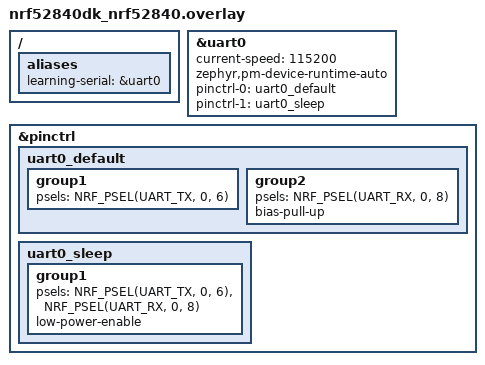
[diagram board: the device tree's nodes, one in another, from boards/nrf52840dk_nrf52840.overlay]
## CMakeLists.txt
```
cmake_minimum_required(VERSION 3.20.0)
find_package(Zephyr REQUIRED HINTS $ENV{ZEPHYR_BASE})

project(learning_zephyr_serial)

target_sources(app PRIVATE 
    src/main.c
    )

add_subdirectory(./src/app_uart)
add_subdirectory_ifdef(CONFIG_APP_USB ./src/app_usb)
```

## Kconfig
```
source "Kconfig.zephyr"

menu "Zephyr Application UART Configuration"
rsource "src/app_uart/Kconfig.app_uart"
endmenu

menu "Application Configuration"
module = APP
module-str = app
source "subsys/logging/Kconfig.template.log_config"
endmenu

menu "Application USB Device Configuration"
rsource "src/app_usb/Kconfig.app_usb"
endmenu
```

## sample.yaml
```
sample:
  description: Learning Zephyr Async Serial Sample
  name: Learning Zephyr Async Serial Sample
tests:
  sample.peripheral.learning_zephyr_serial:
    sysbuild: true
    build_only: true
    integration_platforms:
      - nrf52dk/nrf52832
      - nrf52833dk/nrf52833
      - nrf52840dk/nrf52840
      - nrf5340dk/nrf5340/cpuapp
      - nrf5340dk/nrf5340/cpuapp/ns
      - nrf54l15dk/nrf54l15/cpuapp
      - nrf54lm20dk/nrf54lm20a/cpuapp
      - nrf9151dk/nrf9151/ns
      - nrf9160dk/nrf9160/ns
    platform_allow:
      - nrf52dk/nrf52832
      - nrf52833dk/nrf52833
      - nrf52840dk/nrf52840
      - nrf5340dk/nrf5340/cpuapp
      - nrf5340dk/nrf5340/cpuapp/ns
      - nrf54l15dk/nrf54l15/cpuapp
      - nrf54lm20dk/nrf54lm20a/cpuapp
      - nrf9151dk/nrf9151/ns
      - nrf9160dk/nrf9160/ns
    tags:
      - sysbuild
```

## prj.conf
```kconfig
# use RTT as console
CONFIG_USE_SEGGER_RTT=y
CONFIG_RTT_CONSOLE=y
CONFIG_UART_CONSOLE=n

# enable logging
CONFIG_LOG=y
CONFIG_LOG_BACKEND_RTT=y
CONFIG_LOG_MODE_DEFERRED=y

CONFIG_SEGGER_RTT_MODE_NO_BLOCK_SKIP=y

# use ASYNC uart API
CONFIG_SERIAL=y
CONFIG_UART_ASYNC_API=y

# need k_malloc
CONFIG_HEAP_MEM_POOL_SIZE=4096

# Low power
CONFIG_PM_DEVICE=y
# CONFIG_PM_DEVICE_RUNTIME=y

# buttons for DK
CONFIG_DK_LIBRARY=y
CONFIG_DK_LIBRARY_DYNAMIC_BUTTON_HANDLERS=y

## not enable cross domain UART by default
# CONFIG_APP_UART_GPIO_CROSS_DOMAIN=y
```

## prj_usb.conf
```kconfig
# use RTT as console
CONFIG_USE_SEGGER_RTT=y
CONFIG_RTT_CONSOLE=y
CONFIG_UART_CONSOLE=n

# enable logging
CONFIG_LOG=y
CONFIG_LOG_BACKEND_RTT=y
CONFIG_LOG_MODE_DEFERRED=y

CONFIG_SEGGER_RTT_MODE_NO_BLOCK_SKIP=y

# Reduce USB stack log level
CONFIG_USBD_LOG_LEVEL_WRN=y
CONFIG_UDC_DRIVER_LOG_LEVEL_WRN=y

# Increase RTT buffer to handle burst logs
CONFIG_SEGGER_RTT_BUFFER_SIZE_UP=4096

# use ASYNC uart API
CONFIG_SERIAL=y
CONFIG_UART_ASYNC_API=y

# need k_malloc
CONFIG_HEAP_MEM_POOL_SIZE=8192

# USB buffer pool configuration
CONFIG_UDC_BUF_COUNT=16
CONFIG_UDC_BUF_POOL_SIZE=8192

# Low power
CONFIG_PM_DEVICE=y
CONFIG_PM_DEVICE_RUNTIME=y
# Note:
# uart0 or uart20 is enabled by default in DeviceTree.
# If we don't disable it, the USB example will not have low power mode because the UART is always on.
# So we set PM_DEVICE_RUNTIME to y, to let the UART disable at the beginning.
# You can also set &uart0 or &uart20 status to "disabled" in DeviceTree, in this case, PM_DEVICE_RUNTIME is not needed.

# buttons for DK
CONFIG_DK_LIBRARY=y
CONFIG_DK_LIBRARY_DYNAMIC_BUTTON_HANDLERS=y

# enable USB Device Next Stack
CONFIG_USB_DEVICE_STACK_NEXT=y
CONFIG_USBD_CDC_ACM_CLASS=y

CONFIG_APP_USB=y

# UART interrupt driven
CONFIG_UART_INTERRUPT_DRIVEN=y
CONFIG_UART_LINE_CTRL=y

# enable USB ASYNC Adapter
CONFIG_UART_ASYNC_ADAPTER=y
```

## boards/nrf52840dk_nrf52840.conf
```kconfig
CONFIG_UART_0_ASYNC=y

CONFIG_UART_NRFX_UARTE_ENHANCED_RX=y


## Hardware bytes counter for async uart
# These options are deprecated. Use UART_NRFX_UARTE_ENHANCED_RX instead

# CONFIG_UART_NRFX_UARTE_ENHANCED_RX=n

# CONFIG_UART_0_NRF_HW_ASYNC=y
# CONFIG_UART_0_NRF_HW_ASYNC_TIMER=2

# CONFIG_NRFX_TIMER2=y
```

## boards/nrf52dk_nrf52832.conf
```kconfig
CONFIG_UART_0_ASYNC=y

CONFIG_UART_NRFX_UARTE_ENHANCED_RX=y


## Hardware bytes counter for async uart
# These options are deprecated. Use UART_NRFX_UARTE_ENHANCED_RX instead

# CONFIG_UART_NRFX_UARTE_ENHANCED_RX=n

# CONFIG_UART_0_NRF_HW_ASYNC=y
# CONFIG_UART_0_NRF_HW_ASYNC_TIMER=2

# CONFIG_NRFX_TIMER2=y
```

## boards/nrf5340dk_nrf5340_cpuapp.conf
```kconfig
CONFIG_UART_0_ASYNC=y

CONFIG_UART_NRFX_UARTE_ENHANCED_RX=y
```

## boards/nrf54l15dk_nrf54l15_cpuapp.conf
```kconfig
CONFIG_UART_20_ASYNC=y

CONFIG_UART_NRFX_UARTE_ENHANCED_RX=y
```

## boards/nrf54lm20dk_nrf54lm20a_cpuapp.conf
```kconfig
CONFIG_UART_20_ASYNC=y

CONFIG_UART_NRFX_UARTE_ENHANCED_RX=y
```

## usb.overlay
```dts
/{
    aliases {
        my-usb-serial = &usb_serial0;
    };
};

&zephyr_udc0 {
    status = "okay";
	usb_serial0: cdc_acm_uart0 {
		compatible = "zephyr,cdc-acm-uart";
        status = "okay";
	};
};
```

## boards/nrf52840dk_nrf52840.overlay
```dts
/{
    aliases {
        learning-serial = &uart0;
    };
};

&uart0 {
    status = "okay";
    current-speed = <115200>;
    /delete-property/ hw-flow-control;
    zephyr,pm-device-runtime-auto;
	pinctrl-0 = <&uart0_default>;
	pinctrl-1 = <&uart0_sleep>;
	pinctrl-names = "default", "sleep";
};

// write pinctrl again to remove RTS and CTS pin
&pinctrl {
    uart0_default {
        group1 {
			psels = <NRF_PSEL(UART_TX, 0, 6)>;
		};
		group2 {
			psels = <NRF_PSEL(UART_RX, 0, 8)>;
			bias-pull-up;
		};
    };

    uart0_sleep {
        group1 {
			psels = <NRF_PSEL(UART_TX, 0, 6)>,
				<NRF_PSEL(UART_RX, 0, 8)>;
			low-power-enable;
            // bias-pull-up;
		};
    };
    
};
```

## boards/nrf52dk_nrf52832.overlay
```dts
/{
    aliases {
        learning-serial = &uart0;
    };
};

&uart0 {
    status = "okay";
    current-speed = <115200>;
    /delete-property/ hw-flow-control;
    zephyr,pm-device-runtime-auto;
	pinctrl-0 = <&uart0_default>;
	pinctrl-1 = <&uart0_sleep>;
	pinctrl-names = "default", "sleep";
};

// write pinctrl again to remove RTS and CTS pin
&pinctrl {
	uart0_default: uart0_default {
		group1 {
			psels = <NRF_PSEL(UART_TX, 0, 6)>,
				<NRF_PSEL(UART_RX, 0, 8)>;
		};
	};

	uart0_sleep: uart0_sleep {
		group1 {
			psels = <NRF_PSEL(UART_TX, 0, 6)>,
				<NRF_PSEL(UART_RX, 0, 8)>;
			low-power-enable;
		};
	};
};
```

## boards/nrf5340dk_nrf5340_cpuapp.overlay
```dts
/{
    aliases {
        learning-serial = &uart0;
    };
};

&uart0 {
    status = "okay";
    current-speed = <115200>;
    /delete-property/ hw-flow-control;
    zephyr,pm-device-runtime-auto;
	pinctrl-0 = <&uart0_default>;
	pinctrl-1 = <&uart0_sleep>;
	pinctrl-names = "default", "sleep";
};

// write pinctrl again to remove RTS and CTS pin
&pinctrl {
	uart0_default: uart0_default {
		group1 {
			psels = <NRF_PSEL(UART_TX, 0, 20)>;
		};

		group2 {
			psels = <NRF_PSEL(UART_RX, 0, 22)>;
			bias-pull-up;
		};
	};

	uart0_sleep: uart0_sleep {
		group1 {
			psels = <NRF_PSEL(UART_TX, 0, 20)>,
				<NRF_PSEL(UART_RX, 0, 22)>;
			low-power-enable;
		};
	};
};
```

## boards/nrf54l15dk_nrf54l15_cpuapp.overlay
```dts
/{
    aliases {
        learning-serial = &uart20;
    };
};


&uart20 {
    status = "okay";
    current-speed = <115200>;
    /delete-property/ hw-flow-control;
    zephyr,pm-device-runtime-auto;
    pinctrl-0 = <&uart20_default>;
	pinctrl-1 = <&uart20_sleep>;
	pinctrl-names = "default", "sleep";
};

// write pinctrl again to remove RTS and CTS pin
&pinctrl {
    uart20_default {
		group1 {
			psels = <NRF_PSEL(UART_TX, 1, 4)>;
		};
		group2 {
			psels = <NRF_PSEL(UART_RX, 1, 5)>;
			bias-pull-up;
		};
    };
    uart20_sleep {
		group1 {
			psels = <NRF_PSEL(UART_TX, 1, 4)>,
				<NRF_PSEL(UART_RX, 1, 5)>;
			low-power-enable;
            // bias-pull-up;
		};
    };
};

// // 54L15 GPIO cross-domain usage

// &spi00 {
//     status = "disabled";
// };

// // write pinctrl again to remove RTS and CTS pin
// &pinctrl {
//     uart20_default {
// 		group1 {
// 			psels = <NRF_PSEL(UART_TX, 2, 2)>;
// 		};
// 		group2 {
// 			psels = <NRF_PSEL(UART_RX, 2, 0)>;
// 			bias-pull-up;
// 		};
//     };
//     uart20_sleep {
// 		group1 {
// 			psels = <NRF_PSEL(UART_TX, 2, 2)>,
// 				<NRF_PSEL(UART_RX, 2, 0)>;
// 			low-power-enable;
// 		};
//     };
// };
```

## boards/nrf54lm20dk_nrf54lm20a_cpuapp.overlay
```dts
/{
    aliases {
        learning-serial = &uart20;
    };
};


&uart20 {
    status = "okay";
    current-speed = <115200>;
    /delete-property/ hw-flow-control;
    zephyr,pm-device-runtime-auto;
    pinctrl-0 = <&uart20_default>;
	pinctrl-1 = <&uart20_sleep>;
	pinctrl-names = "default", "sleep";
};

// write pinctrl again to remove RTS and CTS pin
&pinctrl {
	uart20_default: uart20_default {
		group1 {
			psels = <NRF_PSEL(UART_TX, 1, 16)>;
		};

		group2 {
			psels = <NRF_PSEL(UART_RX, 1, 17)>;
			bias-pull-up;
		};
	};

	 uart20_sleep: uart20_sleep {
		group1 {
			psels = <NRF_PSEL(UART_TX, 1, 16)>,
				<NRF_PSEL(UART_RX, 1, 17)>;
			low-power-enable;
		};
	};
};
```

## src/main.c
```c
#include <zephyr/kernel.h>
#include <dk_buttons_and_leds.h>

// nRF91 Series modem library
#if defined(CONFIG_NRF_MODEM_LIB)
#include <modem/nrf_modem_lib.h>
#endif

#include <zephyr/logging/log.h>
LOG_MODULE_REGISTER(app, CONFIG_APP_LOG_LEVEL);

#include "app_uart.h"

/* RX packets buffer */
static uint8_t serial_cmd_buf[256];

/* RX FSM states */
enum protocol_state {
    S_DATA_RECEIVED, // normal data state
    S_CR_RECEIVED, // received '\r' last time
};

static void bytes_to_packet(uint8_t byte)
{
    static uint32_t len = 0;
    static enum protocol_state state = S_DATA_RECEIVED; 

    if (len >= sizeof(serial_cmd_buf)) {
        LOG_WRN("Serial command buffer overflow, resetting");
        // reset
        len = 0;
        state = S_DATA_RECEIVED;
        return;
    }

    serial_cmd_buf[len++] = byte;

    switch(state) {

    case S_DATA_RECEIVED:
        if ('\r' == byte) {
            state = S_CR_RECEIVED;  
        }
        break;


    case S_CR_RECEIVED:
    {   
        if ('\n' == byte) {
            LOG_HEXDUMP_INF(serial_cmd_buf, len, "Received packets:");

            // loopback
            int err = app_uart_tx(serial_cmd_buf, len);
            if (err) {
                LOG_ERR("Failed to send loopback data: %d", err);
            }

            // clear
            len = 0;
            state = S_DATA_RECEIVED;

        } else {
            LOG_WRN("Received \\r, but no \\n after!!!");
            // reset
            len = 0;
            state = S_DATA_RECEIVED;
        }
        break;
    }

    default:
        LOG_ERR("Unknown state!");
        // reset state to prevent infinite error logging
        len = 0;
        state = S_DATA_RECEIVED;
        break;
    }
}

static void uart_callback(uint8_t *byte, size_t len)
{
    if (byte == NULL || len == 0) {
        LOG_WRN("Invalid callback parameters");
        return;
    }
    
    // received are byte streams, we need to transform them into packets
    for (size_t i = 0; i < len; i++) {
        bytes_to_packet(byte[i]);
    }
}

void button_handler(uint32_t button_state, uint32_t has_changed)
{
    uint32_t button = button_state & has_changed;
    if (DK_BTN1_MSK & button) {
        LOG_INF("Suspend UART");
        int err = app_uart_sleep();
        if (err) {
            LOG_ERR("Failed to suspend UART: %d", err);
        }
    }
    if (DK_BTN2_MSK & button) {
        LOG_INF("Resume UART");
        int err = app_uart_wakeup();
        if (err) {
            LOG_ERR("Failed to resume UART: %d", err);
        }
    }
}

int main()
{
    int err;
    
    LOG_INF("Starting UART application");
    
    /* application buttons */
    dk_buttons_init(button_handler);

    /* UART RX init */
    err = app_uart_rx_cb_register(uart_callback);
    if (err) {
        LOG_ERR("Failed to register RX callback: %d", err);
        return err;
    }
    
    LOG_INF("UART application initialized successfully");

#if defined(CONFIG_NRF_MODEM_LIB)
    // for nRF91 Cellular Series, we should init the modem to keep low power,
    // even if we don't use cellular functions here.
    nrf_modem_lib_init();
#endif

    uint8_t start_msg[] = "UART EXAMPLE START\r\n";
    app_uart_tx(start_msg, sizeof(start_msg) - 1);

    k_sleep(K_FOREVER);
    return 0;
}
```
